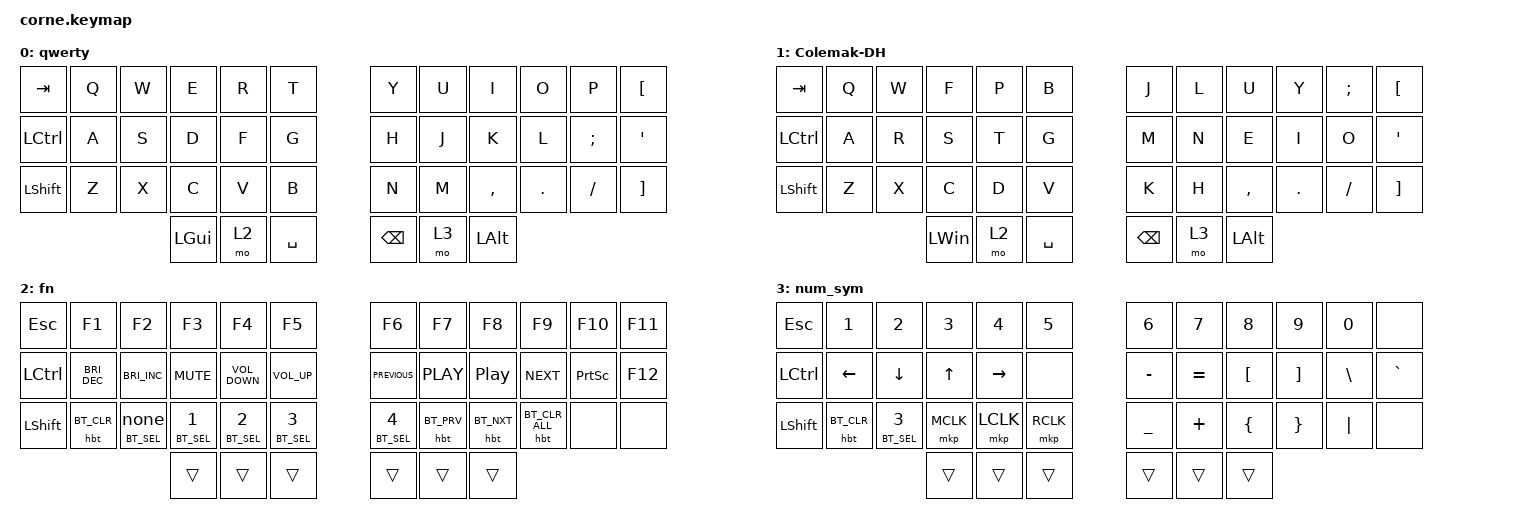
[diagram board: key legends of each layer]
#include <behaviors.dtsi>
#include <dt-bindings/zmk/bt.h>
#include <dt-bindings/zmk/keys.h>
#include <dt-bindings/zmk/mouse.h>

/ {
    combos {
        compatible = "zmk,combos";

        enter {
            bindings = <&kp ENTER>;
            key-positions = <7 8>;
            layers = <0>;
        };

        esc {
            bindings = <&kp ESCAPE>;
            key-positions = <3 4>;
            layers = <0>;
            require-prior-idle-ms = <10>;
        };

        Colemak-DH {
            bindings = <&to 1>;
            key-positions = <19 16>;
        };

        QWERTY {
            bindings = <&to 0>;
            key-positions = <4 7>;
        };
    };

    behaviors {
        hbt: hbt {
            compatible = "zmk,behavior-hold-tap";
            bindings = <&bt>, <&none>;

            #binding-cells = <2>;
            tapping-term-ms = <3000>;
        };
    };

    keymap {
        compatible = "zmk,keymap";

        qwerty {
            bindings = <
&kp TAB    &kp Q  &kp W  &kp E     &kp R  &kp T        &kp Y     &kp U  &kp I      &kp O    &kp P     &kp LBKT
&kp LCTRL  &kp A  &kp S  &kp D     &kp F  &kp G        &kp H     &kp J  &kp K      &kp L    &kp SEMI  &kp SQT
&kp LSHFT  &kp Z  &kp X  &kp C     &kp V  &kp B        &kp N     &kp M  &kp COMMA  &kp DOT  &kp FSLH  &kp RBKT
                         &kp LGUI  &mo 2  &kp SPACE    &kp BSPC  &mo 3  &kp LALT
            >;
        };

        Colemak-DH {
            bindings = <
&kp TAB    &kp Q  &kp W  &kp F         &kp P  &kp B        &kp J          &kp L  &kp U      &kp Y    &kp SEMI  &kp LBKT
&kp LCTRL  &kp A  &kp R  &kp S         &kp T  &kp G        &kp M          &kp N  &kp E      &kp I    &kp O     &kp APOS
&kp LSHFT  &kp Z  &kp X  &kp C         &kp D  &kp V        &kp K          &kp H  &kp COMMA  &kp DOT  &kp FSLH  &kp RBKT
                         &kp LEFT_WIN  &mo 2  &kp SPACE    &kp BACKSPACE  &mo 3  &kp LALT
            >;
        };

        fn {
            bindings = <
&kp ESCAPE      &kp F1                &kp F2         &kp F3         &kp F4             &kp F5           &kp F6          &kp F7       &kp F8            &kp F9           &kp F10          &kp F11
&kp LCTRL       &kp C_BRIGHTNESS_DEC  &kp C_BRI_INC  &kp C_MUTE     &kp C_VOLUME_DOWN  &kp C_VOL_UP     &kp C_PREVIOUS  &kp C_PLAY   &kp C_PLAY_PAUSE  &kp C_NEXT       &kp PRINTSCREEN  &kp F12
&kp LEFT_SHIFT  &hbt BT_CLR           &hbt BT_SEL 0  &hbt BT_SEL 1  &hbt BT_SEL 2      &hbt BT_SEL 3    &hbt BT_SEL 4   &hbt BT_PRV  &hbt BT_NXT       &hbt BT_CLR_ALL  &none            &none
                                                     &trans         &trans             &trans           &trans          &trans       &trans
            >;
        };

        num_sym {
            bindings = <
&kp ESCAPE        &kp NUMBER_1  &kp NUMBER_2   &kp NUMBER_3  &kp NUMBER_4  &kp N5       &kp NUMBER_6  &kp N7     &kp N8    &kp N9    &kp N0    &none
&kp LEFT_CONTROL  &kp LEFT      &kp DOWN       &kp UP        &kp RIGHT     &none        &kp MINUS     &kp EQUAL  &kp LBKT  &kp RBKT  &kp BSLH  &kp GRAVE
&kp LEFT_SHIFT    &hbt BT_CLR   &hbt BT_SEL 3  &mkp MCLK     &mkp LCLK     &mkp RCLK    &kp UNDER     &kp PLUS   &kp LBRC  &kp RBRC  &kp PIPE  &none
                                               &trans        &trans        &trans       &trans        &trans     &trans
            >;
        };
    };
};
